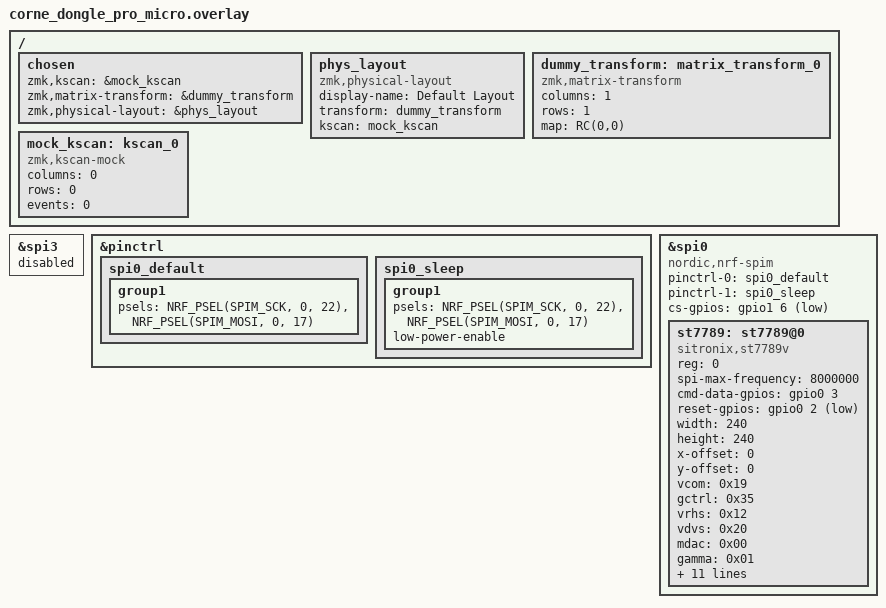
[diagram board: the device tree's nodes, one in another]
/* 1. Отключаем конфликтный SPI3 из стандартного шилда */
/* ДОБАВЬТЕ ЭТУ СТРОКУ В САМЫЙ ВЕРХ ФАЙЛА */
#include <dt-bindings/zmk/matrix_transform.h>
&spi3 {
    status = "disabled";
};

/* 2. Настраиваем пины SPI0 (SCK: 0.22, MOSI: 0.17) */
&pinctrl {
    spi0_default: spi0_default {
        group1 {
            psels = <NRF_PSEL(SPIM_SCK, 0, 22)>,
                    <NRF_PSEL(SPIM_MOSI, 0, 17)>;
        };
    };
    spi0_sleep: spi0_sleep {
        group1 {
            psels = <NRF_PSEL(SPIM_SCK, 0, 22)>,
                    <NRF_PSEL(SPIM_MOSI, 0, 17)>;
            low-power-enable;
        };
    };
};

&spi0 {
    compatible = "nordic,nrf-spim";
    status = "okay";
    pinctrl-0 = <&spi0_default>;
    pinctrl-1 = <&spi0_sleep>;
    pinctrl-names = "default", "sleep";
    cs-gpios = <&gpio1 6 GPIO_ACTIVE_LOW>; // CS на P1.06 (пин 38)

    st7789: st7789@0 {
        compatible = "sitronix,st7789v";
        reg = <0>;
        spi-max-frequency = <8000000>;

        /* Пины управления */
        cmd-data-gpios = <&gpio0 3 GPIO_ACTIVE_HIGH>; // DC
        reset-gpios = <&gpio0 2 GPIO_ACTIVE_LOW>;    // RES

        width = <240>;
        height = <240>;
        x-offset = <0>;
        y-offset = <0>;

        /* ОБЯЗАТЕЛЬНЫЕ ПАРАМЕТРЫ ДЛЯ ЭТОЙ ВЕРСИИ */
        vcom = <0x19>;
        gctrl = <0x35>;
        vrhs = <0x12>;
        vdvs = <0x20>;
        mdac = <0x00>;
        gamma = <0x01>;
        colmod = <0x05>;
        lcm = <0x2c>;

        /* Параметры с суффиксом -param, которые требует компилятор */
        porch-param = [0c 0c 00 33 33];
        cmd2en-param = [5a 69 02 01];
        pwctrl1-param = [a4 a1];
        pvgam-param = [d0 04 0d 11 13 2b 3f 54 4c 18 0d 0b 1f 23];
        nvgam-param = [d0 04 0c 11 13 2c 3f 44 51 2f 1f 1f 20 23];
        ram-param = [00 f0];
        rgb-param = [cd 08 14];
    };
};

/ {
    chosen {
        zmk,kscan = &mock_kscan;
        zmk,matrix-transform = &dummy_transform;
        /* Эта строка лечит ошибку physical_layouts.c */
        zmk,physical-layout = &phys_layout;
    };

    /* Виртуальная раскладка */
    phys_layout: phys_layout {
        compatible = "zmk,physical-layout";
        display-name = "Default Layout";
        transform = <&dummy_transform>;
        kscan = <&mock_kscan>;
    };

    dummy_transform: matrix_transform_0 {
        compatible = "zmk,matrix-transform";
        columns = <1>;
        rows = <1>;
        map = <RC(0,0)>;
    };

    mock_kscan: kscan_0 {
        compatible = "zmk,kscan-mock";
        columns = <0>;
        rows = <0>;
        events = <0>;
    };
};
